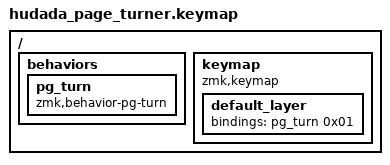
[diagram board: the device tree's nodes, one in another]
// 文件路径: config/hudada_page_turner/hudada_page_turner.keymap

#include "../../custom_service/page_turner_service.h" // 引用我们的行为头文件

/ {
    behaviors {
        // 定义一个名为 pg_turn 的新行为
        pg_turn: pg_turn {
            compatible = "zmk,behavior-pg-turn";
            #binding-cells = <1>; // 行为接受1个参数
        };
    };

    keymap {
        compatible = "zmk,keymap";

        default_layer {
            bindings = <
                &pg_turn 0x01>   // 第一个按键（上翻页）
                &pg_turn 0x02>   // 第二个按键（下翻页）
            >;
        };
    };
};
